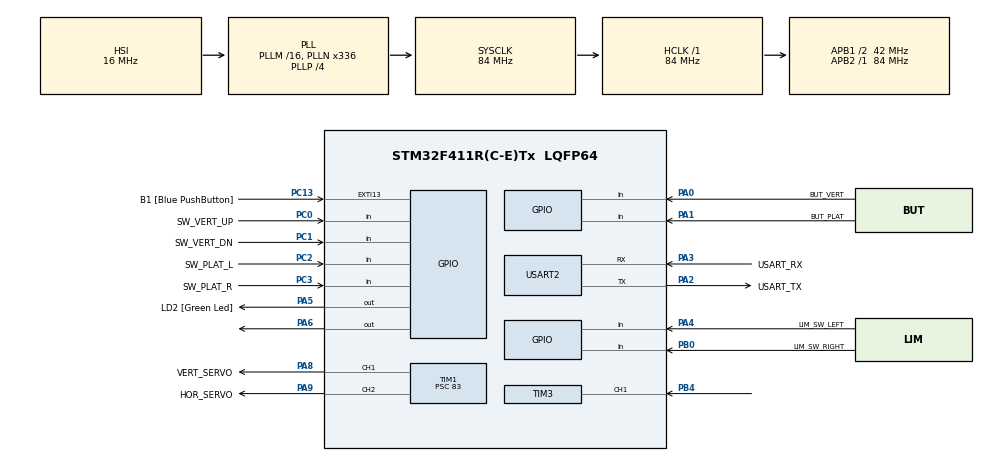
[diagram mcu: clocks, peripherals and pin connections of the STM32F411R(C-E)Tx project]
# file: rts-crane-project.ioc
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FREERTOS.HEAP_NUMBER=1
FREERTOS.Tasks01=defaultTask,24,128,StartDefaultTask,Default,NULL,Dynamic,NULL,NULL
FREERTOS.configUSE_NEWLIB_REENTRANT=1
Mcu.Family=STM32F4
Mcu.Name=STM32F411R(C-E)Tx
Mcu.Package=LQFP64
NVIC.PriorityGroup=NVIC_PRIORITYGROUP_4
NVIC.TIM1_BRK_TIM9_IRQn=true\:5\:0\:false\:false\:true\:false\:false\:true\:true
NVIC.TIM3_IRQn=true\:5\:0\:false\:false\:true\:true\:true\:true\:true
NVIC.TimeBase=TIM1_BRK_TIM9_IRQn
NVIC.TimeBaseIP=TIM9
PA0-WKUP.GPIO_Label=BUT_VERT
PA0-WKUP.GPIO_PuPd=GPIO_PULLDOWN
PA0-WKUP.Signal=GPIO_Input
PA1.GPIO_Label=BUT_PLAT
PA1.GPIO_PuPd=GPIO_PULLDOWN
PA1.Signal=GPIO_Input
PA13.GPIO_Label=TMS
PA13.Mode=Serial_Wire
PA13.Signal=SYS_JTMS-SWDIO
PA14.GPIO_Label=TCK
PA14.Mode=Serial_Wire
PA14.Signal=SYS_JTCK-SWCLK
PA2.GPIO_Label=USART_TX
PA2.Mode=Asynchronous
PA2.Signal=USART2_TX
PA3.GPIO_Label=USART_RX
PA3.Mode=Asynchronous
PA3.Signal=USART2_RX
PA4.GPIO_Label=LIM_SW_LEFT
PA4.GPIO_PuPd=GPIO_PULLDOWN
PA4.Signal=GPIO_Input
PA5.GPIO_Label=LD2 [Green Led]
PA5.Signal=GPIO_Output
PA6.Signal=GPIO_Output
PA8.GPIO_Label=VERT_SERVO
PA8.Signal=S_TIM1_CH1
PA9.GPIO_Label=HOR_SERVO
PA9.Signal=S_TIM1_CH2
PB0.GPIO_Label=LIM_SW_RIGHT
PB0.GPIO_PuPd=GPIO_PULLDOWN
PB0.Signal=GPIO_Input
PB3.GPIO_Label=SWO
PB3.Signal=SYS_JTDO-SWO
PB4.Signal=S_TIM3_CH1
PC0.GPIO_Label=SW_VERT_UP
PC0.GPIO_PuPd=GPIO_PULLDOWN
PC0.Signal=GPIO_Input
PC1.GPIO_Label=SW_VERT_DN
PC1.GPIO_PuPd=GPIO_PULLDOWN
PC1.Signal=GPIO_Input
PC13-ANTI_TAMP.GPIO_Label=B1 [Blue PushButton]
PC13-ANTI_TAMP.GPIO_ModeDefaultEXTI=GPIO_MODE_IT_FALLING
PC13-ANTI_TAMP.Signal=GPXTI13
PC14-OSC32_IN.Mode=LSE-External-Oscillator
PC14-OSC32_IN.Signal=RCC_OSC32_IN
PC15-OSC32_OUT.Mode=LSE-External-Oscillator
PC15-OSC32_OUT.Signal=RCC_OSC32_OUT
PC2.GPIO_Label=SW_PLAT_L
PC2.GPIO_PuPd=GPIO_PULLDOWN
PC2.Signal=GPIO_Input
PC3.GPIO_Label=SW_PLAT_R
PC3.GPIO_PuPd=GPIO_PULLDOWN
PC3.Signal=GPIO_Input
PH0\ -\ OSC_IN.Mode=HSE-External-Clock-Source
PH0\ -\ OSC_IN.Signal=RCC_OSC_IN
PH1\ -\ OSC_OUT.Mode=HSE-External-Clock-Source
PH1\ -\ OSC_OUT.Signal=RCC_OSC_OUT
ProjectManager.HeapSize=0x200
ProjectManager.StackSize=0x400
ProjectManager.TargetToolchain=STM32CubeIDE
RCC.48MHZClocksFreq_Value=84000000
RCC.AHBFreq_Value=84000000
RCC.APB1CLKDivider=RCC_HCLK_DIV2
RCC.APB1Freq_Value=42000000
RCC.APB1TimFreq_Value=84000000
RCC.APB2Freq_Value=84000000
RCC.APB2TimFreq_Value=84000000
RCC.CortexFreq_Value=84000000
RCC.FLatency-AdvancedSettings=FLASH_LATENCY_2
RCC.HCLKFreq_Value=84000000
RCC.HSE_VALUE=8000000
RCC.HSI_VALUE=16000000
RCC.PLLN=336
RCC.PLLP=RCC_PLLP_DIV4
RCC.SYSCLKFreq_VALUE=84000000
RCC.SYSCLKSource=RCC_SYSCLKSOURCE_PLLCLK
RCC.VCOOutputFreq_Value=336000000
SH.S_TIM1_CH1.0=TIM1_CH1,PWM Generation1 CH1
SH.S_TIM1_CH2.0=TIM1_CH2,PWM Generation2 CH2
SH.S_TIM3_CH1.0=TIM3_CH1,Input_Capture1_from_TI1
TIM1.Channel-PWM\ Generation1\ CH1=TIM_CHANNEL_1
TIM1.Channel-PWM\ Generation2\ CH2=TIM_CHANNEL_2
TIM1.Period=19999
TIM1.Prescaler=83
TIM1.Pulse-PWM\ Generation1\ CH1=1500
TIM3.Channel-Input_Capture1_from_TI1=TIM_CHANNEL_1
TIM3.Prescaler=83
USART2.VirtualMode=VM_ASYNC
VP_FREERTOS_VS_CMSIS_V2.Mode=CMSIS_V2
VP_SYS_VS_tim9.Mode=TIM9
board=NUCLEO-F411RE

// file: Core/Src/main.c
/* USER CODE BEGIN Header */
/**
  ******************************************************************************
  * @file           : main.c
  * @brief          : Main program body
  ******************************************************************************
  * @attention
  *
  * Copyright (c) 2022 STMicroelectronics.
  * All rights reserved.
  *
  * This software is licensed under terms that can be found in the LICENSE file
  * in the root directory of this software component.
  * If no LICENSE file comes with this software, it is provided AS-IS.
  *
  ******************************************************************************
  */
/* USER CODE END Header */
#include "main.h"
#include "cmsis_os.h"

/* USER CODE BEGIN Includes */
#include "User/main_user.h"
/* USER CODE END Includes */

TIM_HandleTypeDef htim1;
TIM_HandleTypeDef htim3;

UART_HandleTypeDef huart2;

/* Definitions for defaultTask */
osThreadId_t defaultTaskHandle;
const osThreadAttr_t defaultTask_attributes = {
  .name = "defaultTask",
  .stack_size = 128 * 4,
  .priority = (osPriority_t) osPriorityNormal,
};

void SystemClock_Config(void);
static void MX_GPIO_Init(void);
static void MX_USART2_UART_Init(void);
static void MX_TIM1_Init(void);
static void MX_TIM3_Init(void);
void StartDefaultTask(void *argument);

int main(void)
{

  /* MCU Configuration--------------------------------------------------------*/

  /* Reset of all peripherals, Initializes the Flash interface and the Systick. */
  HAL_Init();

  /* Configure the system clock */
  SystemClock_Config();

  /* Initialize all configured peripherals */
  MX_GPIO_Init();
  MX_USART2_UART_Init();
  MX_TIM1_Init();
  MX_TIM3_Init();
  /* USER CODE BEGIN 2 */
  main_user();
#if 0
  /* USER CODE END 2 */

  /* Init scheduler */
  osKernelInitialize();

  /* Create the thread(s) */
  /* creation of defaultTask */
  defaultTaskHandle = osThreadNew(StartDefaultTask, NULL, &defaultTask_attributes);

  /* Start scheduler */
  osKernelStart();

  /* We should never get here as control is now taken by the scheduler */

  /* Infinite loop */
  /* USER CODE BEGIN WHILE */
#endif
  while (1)
  {
    /* USER CODE END WHILE */

  }
}

void SystemClock_Config(void)
{
  RCC_OscInitTypeDef RCC_OscInitStruct = {0};
  RCC_ClkInitTypeDef RCC_ClkInitStruct = {0};

  /** Configure the main internal regulator output voltage
  */
  __HAL_RCC_PWR_CLK_ENABLE();
  __HAL_PWR_VOLTAGESCALING_CONFIG(PWR_REGULATOR_VOLTAGE_SCALE1);

  /** Initializes the RCC Oscillators according to the specified parameters
  * in the RCC_OscInitTypeDef structure.
  */
  RCC_OscInitStruct.OscillatorType = RCC_OSCILLATORTYPE_HSI;
  RCC_OscInitStruct.HSIState = RCC_HSI_ON;
  RCC_OscInitStruct.HSICalibrationValue = RCC_HSICALIBRATION_DEFAULT;
  RCC_OscInitStruct.PLL.PLLState = RCC_PLL_ON;
  RCC_OscInitStruct.PLL.PLLSource = RCC_PLLSOURCE_HSI;
  RCC_OscInitStruct.PLL.PLLM = 16;
  RCC_OscInitStruct.PLL.PLLN = 336;
  RCC_OscInitStruct.PLL.PLLP = RCC_PLLP_DIV4;
  RCC_OscInitStruct.PLL.PLLQ = 4;
  if (HAL_RCC_OscConfig(&RCC_OscInitStruct) != HAL_OK)
  {
    Error_Handler();
  }

  /** Initializes the CPU, AHB and APB buses clocks
  */
  RCC_ClkInitStruct.ClockType = RCC_CLOCKTYPE_HCLK|RCC_CLOCKTYPE_SYSCLK
                              |RCC_CLOCKTYPE_PCLK1|RCC_CLOCKTYPE_PCLK2;
  RCC_ClkInitStruct.SYSCLKSource = RCC_SYSCLKSOURCE_PLLCLK;
  RCC_ClkInitStruct.AHBCLKDivider = RCC_SYSCLK_DIV1;
  RCC_ClkInitStruct.APB1CLKDivider = RCC_HCLK_DIV2;
  RCC_ClkInitStruct.APB2CLKDivider = RCC_HCLK_DIV1;

  if (HAL_RCC_ClockConfig(&RCC_ClkInitStruct, FLASH_LATENCY_2) != HAL_OK)
  {
    Error_Handler();
  }
}

static void MX_TIM1_Init(void)
{

  TIM_MasterConfigTypeDef sMasterConfig = {0};
  TIM_OC_InitTypeDef sConfigOC = {0};
  TIM_BreakDeadTimeConfigTypeDef sBreakDeadTimeConfig = {0};

  htim1.Instance = TIM1;
  htim1.Init.Prescaler = 83;
  htim1.Init.CounterMode = TIM_COUNTERMODE_UP;
  htim1.Init.Period = 19999;
  htim1.Init.ClockDivision = TIM_CLOCKDIVISION_DIV1;
  htim1.Init.RepetitionCounter = 0;
  htim1.Init.AutoReloadPreload = TIM_AUTORELOAD_PRELOAD_DISABLE;
  if (HAL_TIM_PWM_Init(&htim1) != HAL_OK)
  {
    Error_Handler();
  }
  sMasterConfig.MasterOutputTrigger = TIM_TRGO_RESET;
  sMasterConfig.MasterSlaveMode = TIM_MASTERSLAVEMODE_DISABLE;
  if (HAL_TIMEx_MasterConfigSynchronization(&htim1, &sMasterConfig) != HAL_OK)
  {
    Error_Handler();
  }
  sConfigOC.OCMode = TIM_OCMODE_PWM1;
  sConfigOC.Pulse = 1500;
  sConfigOC.OCPolarity = TIM_OCPOLARITY_HIGH;
  sConfigOC.OCNPolarity = TIM_OCNPOLARITY_HIGH;
  sConfigOC.OCFastMode = TIM_OCFAST_DISABLE;
  sConfigOC.OCIdleState = TIM_OCIDLESTATE_RESET;
  sConfigOC.OCNIdleState = TIM_OCNIDLESTATE_RESET;
  if (HAL_TIM_PWM_ConfigChannel(&htim1, &sConfigOC, TIM_CHANNEL_1) != HAL_OK)
  {
    Error_Handler();
  }
  sConfigOC.Pulse = 0;
  if (HAL_TIM_PWM_ConfigChannel(&htim1, &sConfigOC, TIM_CHANNEL_2) != HAL_OK)
  {
    Error_Handler();
  }
  sBreakDeadTimeConfig.OffStateRunMode = TIM_OSSR_DISABLE;
  sBreakDeadTimeConfig.OffStateIDLEMode = TIM_OSSI_DISABLE;
  sBreakDeadTimeConfig.LockLevel = TIM_LOCKLEVEL_OFF;
  sBreakDeadTimeConfig.DeadTime = 0;
  sBreakDeadTimeConfig.BreakState = TIM_BREAK_DISABLE;
  sBreakDeadTimeConfig.BreakPolarity = TIM_BREAKPOLARITY_HIGH;
  sBreakDeadTimeConfig.AutomaticOutput = TIM_AUTOMATICOUTPUT_DISABLE;
  if (HAL_TIMEx_ConfigBreakDeadTime(&htim1, &sBreakDeadTimeConfig) != HAL_OK)
  {
    Error_Handler();
  }
  HAL_TIM_MspPostInit(&htim1);

}

static void MX_TIM3_Init(void)
{

  TIM_MasterConfigTypeDef sMasterConfig = {0};
  TIM_IC_InitTypeDef sConfigIC = {0};

  htim3.Instance = TIM3;
  htim3.Init.Prescaler = 83;
  htim3.Init.CounterMode = TIM_COUNTERMODE_UP;
  htim3.Init.Period = 65535;
  htim3.Init.ClockDivision = TIM_CLOCKDIVISION_DIV1;
  htim3.Init.AutoReloadPreload = TIM_AUTORELOAD_PRELOAD_DISABLE;
  if (HAL_TIM_IC_Init(&htim3) != HAL_OK)
  {
    Error_Handler();
  }
  sMasterConfig.MasterOutputTrigger = TIM_TRGO_RESET;
  sMasterConfig.MasterSlaveMode = TIM_MASTERSLAVEMODE_DISABLE;
  if (HAL_TIMEx_MasterConfigSynchronization(&htim3, &sMasterConfig) != HAL_OK)
  {
    Error_Handler();
  }
  sConfigIC.ICPolarity = TIM_INPUTCHANNELPOLARITY_RISING;
  sConfigIC.ICSelection = TIM_ICSELECTION_DIRECTTI;
  sConfigIC.ICPrescaler = TIM_ICPSC_DIV1;
  sConfigIC.ICFilter = 0;
  if (HAL_TIM_IC_ConfigChannel(&htim3, &sConfigIC, TIM_CHANNEL_1) != HAL_OK)
  {
    Error_Handler();
  }

}

static void MX_USART2_UART_Init(void)
{

  huart2.Instance = USART2;
  huart2.Init.BaudRate = 115200;
  huart2.Init.WordLength = UART_WORDLENGTH_8B;
  huart2.Init.StopBits = UART_STOPBITS_1;
  huart2.Init.Parity = UART_PARITY_NONE;
  huart2.Init.Mode = UART_MODE_TX_RX;
  huart2.Init.HwFlowCtl = UART_HWCONTROL_NONE;
  huart2.Init.OverSampling = UART_OVERSAMPLING_16;
  if (HAL_UART_Init(&huart2) != HAL_OK)
  {
    Error_Handler();
  }

}

static void MX_GPIO_Init(void)
{
  GPIO_InitTypeDef GPIO_InitStruct = {0};

  /* GPIO Ports Clock Enable */
  __HAL_RCC_GPIOC_CLK_ENABLE();
  __HAL_RCC_GPIOH_CLK_ENABLE();
  __HAL_RCC_GPIOA_CLK_ENABLE();
  __HAL_RCC_GPIOB_CLK_ENABLE();

  /*Configure GPIO pin Output Level */
  HAL_GPIO_WritePin(GPIOA, LD2_Pin|GPIO_PIN_6, GPIO_PIN_RESET);

  /*Configure GPIO pin : B1_Pin */
  GPIO_InitStruct.Pin = B1_Pin;
  GPIO_InitStruct.Mode = GPIO_MODE_IT_FALLING;
  GPIO_InitStruct.Pull = GPIO_NOPULL;
  HAL_GPIO_Init(B1_GPIO_Port, &GPIO_InitStruct);

  /*Configure GPIO pins : SW_VERT_UP_Pin SW_VERT_DN_Pin SW_PLAT_L_Pin SW_PLAT_R_Pin */
  GPIO_InitStruct.Pin = SW_VERT_UP_Pin|SW_VERT_DN_Pin|SW_PLAT_L_Pin|SW_PLAT_R_Pin;
  GPIO_InitStruct.Mode = GPIO_MODE_INPUT;
  GPIO_InitStruct.Pull = GPIO_PULLDOWN;
  HAL_GPIO_Init(GPIOC, &GPIO_InitStruct);

  /*Configure GPIO pins : BUT_VERT_Pin BUT_PLAT_Pin LIM_SW_LEFT_Pin */
  GPIO_InitStruct.Pin = BUT_VERT_Pin|BUT_PLAT_Pin|LIM_SW_LEFT_Pin;
  GPIO_InitStruct.Mode = GPIO_MODE_INPUT;
  GPIO_InitStruct.Pull = GPIO_PULLDOWN;
  HAL_GPIO_Init(GPIOA, &GPIO_InitStruct);

  /*Configure GPIO pins : LD2_Pin PA6 */
  GPIO_InitStruct.Pin = LD2_Pin|GPIO_PIN_6;
  GPIO_InitStruct.Mode = GPIO_MODE_OUTPUT_PP;
  GPIO_InitStruct.Pull = GPIO_NOPULL;
  GPIO_InitStruct.Speed = GPIO_SPEED_FREQ_LOW;
  HAL_GPIO_Init(GPIOA, &GPIO_InitStruct);

  /*Configure GPIO pin : LIM_SW_RIGHT_Pin */
  GPIO_InitStruct.Pin = LIM_SW_RIGHT_Pin;
  GPIO_InitStruct.Mode = GPIO_MODE_INPUT;
  GPIO_InitStruct.Pull = GPIO_PULLDOWN;
  HAL_GPIO_Init(LIM_SW_RIGHT_GPIO_Port, &GPIO_InitStruct);

}

void StartDefaultTask(void *argument)
{
  for(;;)
  {
    osDelay(1);
  }
}

void HAL_TIM_PeriodElapsedCallback(TIM_HandleTypeDef *htim)
{
  if (htim->Instance == TIM9)
  {
    HAL_IncTick();
  }
}

void Error_Handler(void)
{
  __disable_irq();
  while (1)
  {
  }
}
